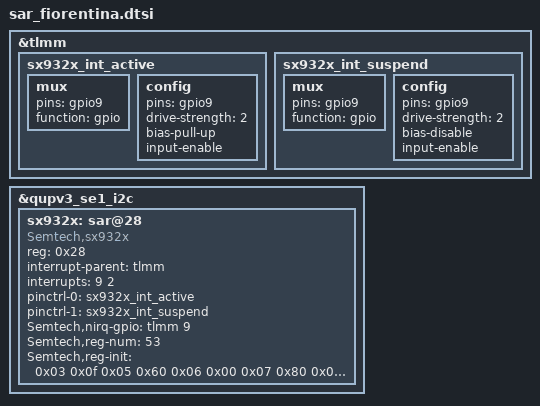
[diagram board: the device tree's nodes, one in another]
&tlmm {
	/* SAR sensor INT */
	sx932x_int_active: sx932x_int_active {
		mux {
			pins = "gpio9";
			function = "gpio";
		};
		config {
			pins = "gpio9";
			drive-strength = <2>;
			bias-pull-up;
			input-enable;
		};
	};
	sx932x_int_suspend: sx932x_int_suspend {
		mux {
			pins = "gpio9";
			function = "gpio";
		};
		config {
			pins = "gpio9";
			drive-strength = <2>;
			bias-disable;
			input-enable;
		};
	};
};

&qupv3_se1_i2c {
	status = "okay";
	sx932x:sar@28 {
		compatible = "Semtech,sx932x";
		reg = <0x28>;
		interrupt-parent = <&tlmm>;
		interrupts = <9 2>;
		interrupt-names = "sx932x_irq";
		pinctrl-names = "sx932x_active", "sx932x_sleep";
		pinctrl-0 = <&sx932x_int_active>;
		pinctrl-1 = <&sx932x_int_suspend >;
		Semtech,nirq-gpio = <&tlmm 9 0x00>;
		status ="ok";
		Semtech,reg-num = <53>;
		Semtech,reg-init  = /bits/ 8 < 0x03 0x0f
			0x05 0x60
			0x06 0x00
			0x07 0x80
			0x08 0x00
			0x10 0x16
			0x14 0x00 /*PH0 to CS0 input*/
			0x15 0x00
			0x20 0x10 /*PH2 CS2-input,CS1-dync,CS0-HZ*/
			0x21 0x10
			0x22 0x00
			0x23 0x01
			0x24 0x17
			0x25 0x00
			0x26 0x01
			0x27 0x17
			0x28 0x3D
			0x29 0x27
			0x2A 0x1F
			0x2B 0x37
			0x2C 0x12
			0x2D 0x06
			0x30 0x0A
			0x31 0x08
			0x32 0x20
			0x33 0x20
			0x34 0x0B
			0x35 0x10
			0x36 0x20
			0x37 0x24
			0x40 0x00
			0x41 0x00
			0x42 0x00
			0x43 0x00
			0x44 0x00
			0x45 0x05
			0x46 0x00
			0x47 0x00
			0x48 0x00
			0x49 0x00
			0x4A 0x40
			0x4B 0x00
			0x4C 0x00
			0x4D 0x00
			0x4E 0x80
			0x4F 0x0C
			0x50 0x00
			0x51 0x00
			0x52 0x00
			0x53 0x00
			0x54 0x00
			0x60 0x01
			0x11 0x21>;
	};
};
